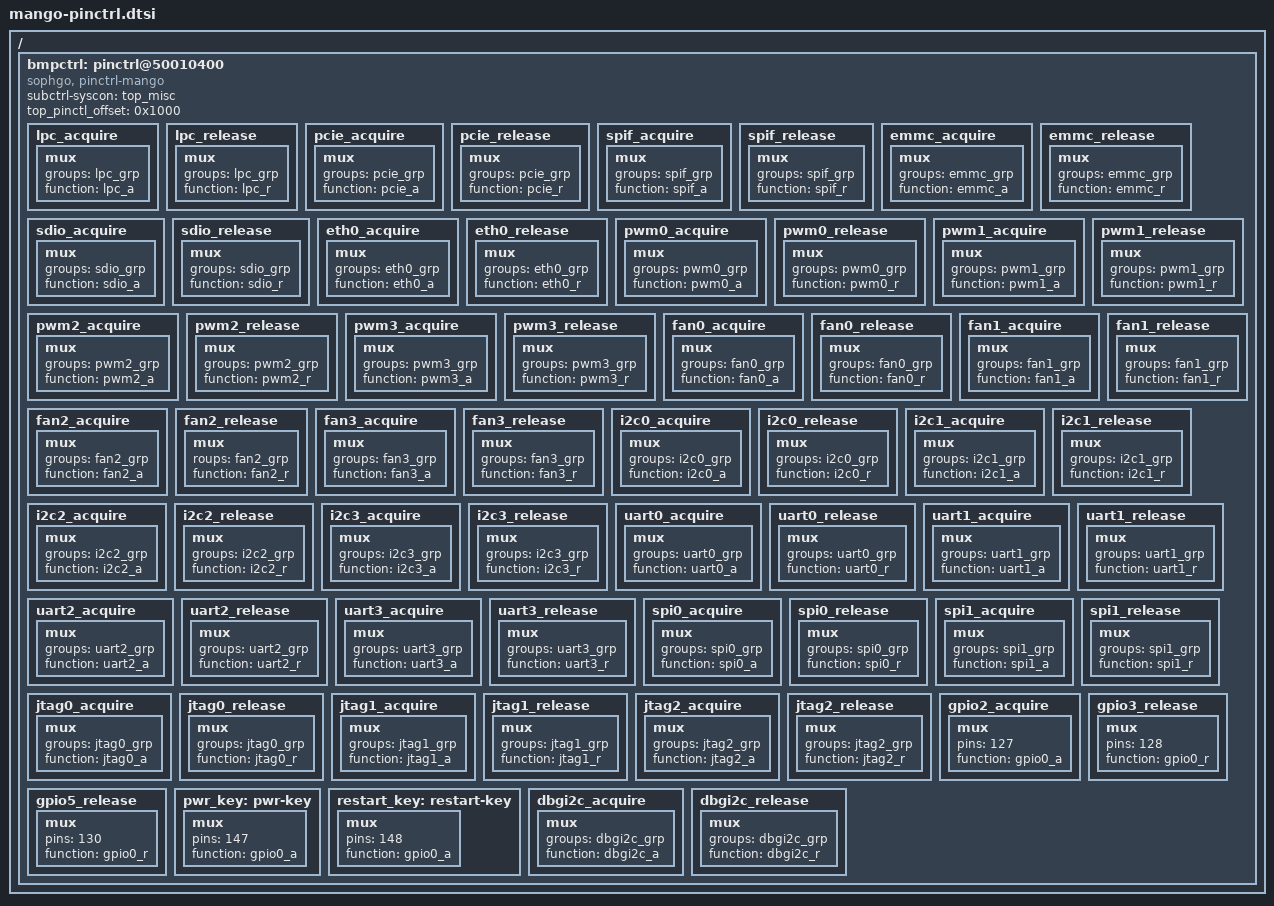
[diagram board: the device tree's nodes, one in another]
/ {
	bmpctrl: pinctrl@50010400 {
		compatible = "sophgo, pinctrl-mango";
		subctrl-syscon = <&top_misc>;
		top_pinctl_offset = <0x1000>;

		lpc_acquire: lpc_acquire {
			mux {
				groups = "lpc_grp";
				function = "lpc_a";
			};
		};

		lpc_release: lpc_release{
			mux {
				groups = "lpc_grp";
				function = "lpc_r";
			};
		};

		pcie_acquire: pcie_acquire {
			mux {
				groups = "pcie_grp";
				function = "pcie_a";
			};
		};

		pcie_release: pcie_release{
			mux {
				groups = "pcie_grp";
				function = "pcie_r";
			};
		};

		spif_acquire: spif_acquire {
			mux {
				groups = "spif_grp";
				function = "spif_a";
			};
		};

		spif_release: spif_release{
			mux {
				groups = "spif_grp";
				function = "spif_r";
			};
		};

		emmc_acquire: emmc_acquire {
			mux {
				groups = "emmc_grp";
				function = "emmc_a";
			};
		};

		emmc_release: emmc_release{
			mux {
				groups = "emmc_grp";
				function = "emmc_r";
			};
		};

		sdio_acquire: sdio_acquire {
			mux {
				groups = "sdio_grp";
				function = "sdio_a";
			};
		};

		sdio_release: sdio_release{
			mux {
				groups = "sdio_grp";
				function = "sdio_r";
			};
		};

		eth0_acquire: eth0_acquire {
			mux {
				groups = "eth0_grp";
				function = "eth0_a";
			};
		};

		eth0_release: eth0_release{
			mux {
				groups = "eth0_grp";
				function = "eth0_r";
			};
		};

		pwm0_acquire: pwm0_acquire {
			mux {
				groups = "pwm0_grp";
				function = "pwm0_a";
			};
		};

		pwm0_release: pwm0_release{
			mux {
				groups = "pwm0_grp";
				function = "pwm0_r";
			};
		};

		pwm1_acquire: pwm1_acquire {
			mux {
				groups = "pwm1_grp";
				function = "pwm1_a";
			};
		};

		pwm1_release: pwm1_release{
			mux {
				groups = "pwm1_grp";
				function = "pwm1_r";
			};
		};

		pwm2_acquire: pwm2_acquire {
			mux {
				groups = "pwm2_grp";
				function = "pwm2_a";
			};
		};

		pwm2_release: pwm2_release{
			mux {
				groups = "pwm2_grp";
				function = "pwm2_r";
			};
		};

		pwm3_acquire: pwm3_acquire {
			mux {
				groups = "pwm3_grp";
				function = "pwm3_a";
			};
		};

		pwm3_release: pwm3_release{
			mux {
				groups = "pwm3_grp";
				function = "pwm3_r";
			};
		};

		fan0_acquire: fan0_acquire {
			mux {
				groups = "fan0_grp";
				function = "fan0_a";
			};
		};

		fan0_release: fan0_release{
			mux {
				groups = "fan0_grp";
				function = "fan0_r";
			};
		};

		fan1_acquire: fan1_acquire {
			mux {
				groups = "fan1_grp";
				function = "fan1_a";
			};
		};

		fan1_release: fan1_release{
			mux {
				groups = "fan1_grp";
				function = "fan1_r";
			};
		};

		fan2_acquire: fan2_acquire {
			mux {
				groups = "fan2_grp";
				function = "fan2_a";
			};
		};

		fan2_release: fan2_release{
			mux {
				roups = "fan2_grp";
				function = "fan2_r";
			};
		};

		fan3_acquire: fan3_acquire {
			mux {
				groups = "fan3_grp";
				function = "fan3_a";
			};
		};

		fan3_release: fan3_release{
			mux {
				groups = "fan3_grp";
				function = "fan3_r";
			};
		};

		i2c0_acquire: i2c0_acquire {
			mux {
				groups = "i2c0_grp";
				function = "i2c0_a";
			};
		};

		i2c0_release: i2c0_release{
			mux {
				groups = "i2c0_grp";
				function = "i2c0_r";
			};
		};

		i2c1_acquire: i2c1_acquire {
			mux {
				groups = "i2c1_grp";
				function = "i2c1_a";
			};
		};

		i2c1_release: i2c1_release{
			mux {
				groups = "i2c1_grp";
				function = "i2c1_r";
			};
		};

		i2c2_acquire: i2c2_acquire {
			mux {
				groups = "i2c2_grp";
				function = "i2c2_a";
			};
		};

		i2c2_release: i2c2_release{
			mux {
				groups = "i2c2_grp";
				function = "i2c2_r";
			};
		};

		i2c3_acquire: i2c3_acquire {
			mux {
				groups = "i2c3_grp";
				function = "i2c3_a";
			};
		};

		i2c3_release: i2c3_release{
			mux {
				groups = "i2c3_grp";
				function = "i2c3_r";
			};
		};

		uart0_acquire: uart0_acquire {
			mux {
				groups = "uart0_grp";
				function = "uart0_a";
			};
		};

		uart0_release: uart0_release{
			mux {
				groups = "uart0_grp";
				function = "uart0_r";
			};
		};

		uart1_acquire: uart1_acquire {
			mux {
				groups = "uart1_grp";
				function = "uart1_a";
			};
		};

		uart1_release: uart1_release{
			mux {
				groups = "uart1_grp";
				function = "uart1_r";
			};
		};

		uart2_acquire: uart2_acquire {
			mux {
				groups = "uart2_grp";
				function = "uart2_a";
			};
		};

		uart2_release: uart2_release{
			mux {
				groups = "uart2_grp";
				function = "uart2_r";
			};
		};

		uart3_acquire: uart3_acquire {
			mux {
				groups = "uart3_grp";
				function = "uart3_a";
			};
		};

		uart3_release: uart3_release{
			mux {
				groups = "uart3_grp";
				function = "uart3_r";
			};
		};

		spi0_acquire: spi0_acquire {
			mux {
				groups = "spi0_grp";
				function = "spi0_a";
			};
		};

		spi0_release: spi0_release{
			mux {
				groups = "spi0_grp";
				function = "spi0_r";
			};
		};

		spi1_acquire: spi1_acquire {
			mux {
				groups = "spi1_grp";
				function = "spi1_a";
			};
		};

		spi1_release: spi1_release{
			mux {
				groups = "spi1_grp";
				function = "spi1_r";
			};
		};

		jtag0_acquire: jtag0_acquire {
			mux {
				groups = "jtag0_grp";
				function = "jtag0_a";
			};
		};

		jtag0_release: jtag0_release{
			mux {
				groups = "jtag0_grp";
				function = "jtag0_r";
			};
		};

		jtag1_acquire: jtag1_acquire {
			mux {
				groups = "jtag1_grp";
				function = "jtag1_a";
			};
		};

		jtag1_release: jtag1_release{
			mux {
				groups = "jtag1_grp";
				function = "jtag1_r";
			};
		};

		jtag2_acquire: jtag2_acquire {
			mux {
				groups = "jtag2_grp";
				function = "jtag2_a";
			};
		};

		jtag2_release: jtag2_release{
			mux {
				groups = "jtag2_grp";
				function = "jtag2_r";
			};
		};

		gpio2_acquire: gpio2_acquire {
			mux {
				pins = <127>;
				function = "gpio0_a";
			};
		};

		gpio3_release: gpio3_release {
			mux {
				pins = <128>;
				function = "gpio0_r";
			};
		};

		gpio5_release: gpio5_release {
			mux {
				pins = <130>;
				function = "gpio0_r";
			};
		};

		pwr_key: pwr-key {
			mux {
				pins = <147>;
				function = "gpio0_a";
			};
		};

		restart_key: restart-key {
			mux {
				pins = <148>;
				function = "gpio0_a";
			};
		};

		dbgi2c_acquire: dbgi2c_acquire {
			mux {
				groups = "dbgi2c_grp";
				function = "dbgi2c_a";
			};
		};

		dbgi2c_release: dbgi2c_release{
			mux {
				groups = "dbgi2c_grp";
				function = "dbgi2c_r";
			};
		};
	};
};
